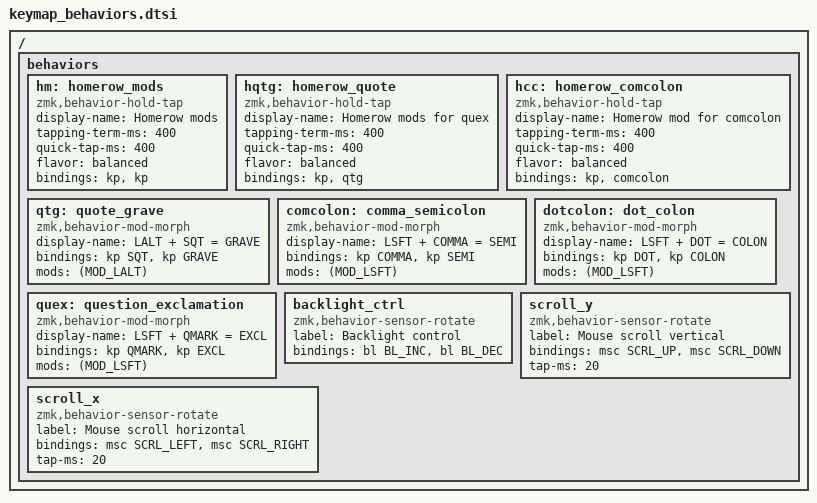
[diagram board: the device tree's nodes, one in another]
/ {
    behaviors {

        // hold-taps 
        hm: homerow_mods {
            display-name = "Homerow mods";
            compatible = "zmk,behavior-hold-tap";
            #binding-cells = <2>;
            tapping-term-ms = <400>;
            quick-tap-ms = <400>;
            flavor = "balanced";
            bindings = <&kp>, <&kp>;
        };

        hqtg: homerow_quote {
            display-name = "Homerow mods for quex";
            compatible = "zmk,behavior-hold-tap";
            #binding-cells = <2>;
            tapping-term-ms = <400>;
            quick-tap-ms = <400>;
            flavor = "balanced";
            bindings = <&kp>, <&qtg>;
        };

        hcc: homerow_comcolon {
            display-name = "Homerow mod for comcolon";
            compatible = "zmk,behavior-hold-tap";
            #binding-cells = <2>;
            tapping-term-ms = <400>;
            quick-tap-ms = <400>;
            flavor = "balanced";
            bindings = <&kp>, <&comcolon>;
        };

        // mod-morphs

        qtg: quote_grave {
            display-name = "LALT + SQT = GRAVE";
            compatible = "zmk,behavior-mod-morph";
            #binding-cells = <0>;
            bindings = <&kp SQT>, <&kp GRAVE>;
            mods = <(MOD_LALT)>;
        };

        comcolon: comma_semicolon {
            display-name = "LSFT + COMMA = SEMI";
            compatible = "zmk,behavior-mod-morph";
            #binding-cells = <0>;
            bindings = <&kp COMMA>, <&kp SEMI>;
            mods = <(MOD_LSFT)>;
        };

        dotcolon: dot_colon {
            display-name = "LSFT + DOT = COLON";
            compatible = "zmk,behavior-mod-morph";
            #binding-cells = <0>;
            bindings = <&kp DOT>, <&kp COLON>;
            mods = <(MOD_LSFT)>;
        };

        quex: question_exclamation {
            display-name = "LSFT + QMARK = EXCL";
            compatible = "zmk,behavior-mod-morph";
            #binding-cells = <0>;
            bindings = <&kp QMARK>, <&kp EXCL>;
            mods = <(MOD_LSFT)>;
        };

        // sensors

        backlight_ctrl: backlight_ctrl {
            label = "Backlight control";
            compatible = "zmk,behavior-sensor-rotate";
            #sensor-binding-cells = <0>;
            bindings = <&bl BL_INC>, <&bl BL_DEC>;
        };

        scroll_y: scroll_y {
            label = "Mouse scroll vertical";
            compatible = "zmk,behavior-sensor-rotate";
            #sensor-binding-cells = <0>;
            bindings = <&msc SCRL_UP>, <&msc SCRL_DOWN>;
            tap-ms = <20>;
        };

        scroll_x: scroll_x {
            label = "Mouse scroll horizontal";
            compatible = "zmk,behavior-sensor-rotate";
            #sensor-binding-cells = <0>;
            bindings = <&msc SCRL_LEFT>, <&msc SCRL_RIGHT>;
            tap-ms = <20>;
        };
    };

};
